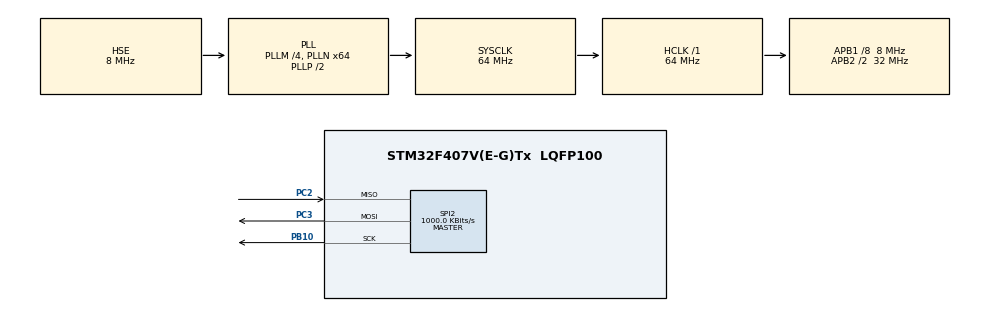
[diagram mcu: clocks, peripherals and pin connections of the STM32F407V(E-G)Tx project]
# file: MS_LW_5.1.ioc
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Mcu.Family=STM32F4
Mcu.Name=STM32F407V(E-G)Tx
Mcu.Package=LQFP100
NVIC.PriorityGroup=NVIC_PRIORITYGROUP_0
PB10.Mode=Full_Duplex_Master
PB10.Signal=SPI2_SCK
PC2.Mode=Full_Duplex_Master
PC2.Signal=SPI2_MISO
PC3.Mode=Full_Duplex_Master
PC3.Signal=SPI2_MOSI
PH0-OSC_IN.Mode=HSE-External-Oscillator
PH0-OSC_IN.Signal=RCC_OSC_IN
PH1-OSC_OUT.Mode=HSE-External-Oscillator
PH1-OSC_OUT.Signal=RCC_OSC_OUT
ProjectManager.HeapSize=0x200
ProjectManager.StackSize=0x400
ProjectManager.TargetToolchain=STM32CubeIDE
RCC.48MHZClocksFreq_Value=18285714.285714287
RCC.AHBFreq_Value=64000000
RCC.APB1CLKDivider=RCC_HCLK_DIV8
RCC.APB1Freq_Value=8000000
RCC.APB1TimFreq_Value=16000000
RCC.APB2CLKDivider=RCC_HCLK_DIV2
RCC.APB2Freq_Value=32000000
RCC.APB2TimFreq_Value=64000000
RCC.CortexFreq_Value=64000000
RCC.HCLKFreq_Value=64000000
RCC.HSE_VALUE=8000000
RCC.HSI_VALUE=16000000
RCC.PLLM=4
RCC.PLLN=64
RCC.PLLQ=7
RCC.PLLSourceVirtual=RCC_PLLSOURCE_HSE
RCC.SYSCLKFreq_VALUE=64000000
RCC.SYSCLKSource=RCC_SYSCLKSOURCE_PLLCLK
RCC.VCOOutputFreq_Value=128000000
SPI2.BaudRatePrescaler=SPI_BAUDRATEPRESCALER_8
SPI2.CalculateBaudRate=1000.0 KBits/s
SPI2.Direction=SPI_DIRECTION_2LINES
SPI2.Mode=SPI_MODE_MASTER
SPI2.VirtualType=VM_MASTER
board=STM32F407G-DISC1

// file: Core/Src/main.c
/* USER CODE BEGIN Header */
/**
  ******************************************************************************
  * @file           : main.c
  * @brief          : Main program body
  ******************************************************************************
  * @attention
  *
  * Copyright (c) 2023 STMicroelectronics.
  * All rights reserved.
  *
  * This software is licensed under terms that can be found in the LICENSE file
  * in the root directory of this software component.
  * If no LICENSE file comes with this software, it is provided AS-IS.
  *
  ******************************************************************************
  */
/* USER CODE END Header */
#include "main.h"

SPI_HandleTypeDef hspi2;

/* USER CODE BEGIN PV */
uint8_t buffer_tx[4] = {1, 3, 11, 15};
uint8_t buffer_rx[4];
/* USER CODE END PV */

void SystemClock_Config(void);
static void MX_GPIO_Init(void);
static void MX_SPI2_Init(void);

int main(void)
{

  /* MCU Configuration--------------------------------------------------------*/

  /* Reset of all peripherals, Initializes the Flash interface and the Systick. */
  HAL_Init();

  /* Configure the system clock */
  SystemClock_Config();

  /* Initialize all configured peripherals */
  MX_GPIO_Init();
  MX_SPI2_Init();
  /* USER CODE BEGIN 2 */
HAL_SPI_TransmitReceive(&hspi2, buffer_tx, buffer_rx, 4, 100);
  /* USER CODE END 2 */

  /* Infinite loop */
  while (1)
  {

  }
}

void SystemClock_Config(void)
{
  RCC_OscInitTypeDef RCC_OscInitStruct = {0};
  RCC_ClkInitTypeDef RCC_ClkInitStruct = {0};

  /** Configure the main internal regulator output voltage
  */
  __HAL_RCC_PWR_CLK_ENABLE();
  __HAL_PWR_VOLTAGESCALING_CONFIG(PWR_REGULATOR_VOLTAGE_SCALE1);

  /** Initializes the RCC Oscillators according to the specified parameters
  * in the RCC_OscInitTypeDef structure.
  */
  RCC_OscInitStruct.OscillatorType = RCC_OSCILLATORTYPE_HSE;
  RCC_OscInitStruct.HSEState = RCC_HSE_ON;
  RCC_OscInitStruct.PLL.PLLState = RCC_PLL_ON;
  RCC_OscInitStruct.PLL.PLLSource = RCC_PLLSOURCE_HSE;
  RCC_OscInitStruct.PLL.PLLM = 4;
  RCC_OscInitStruct.PLL.PLLN = 64;
  RCC_OscInitStruct.PLL.PLLP = RCC_PLLP_DIV2;
  RCC_OscInitStruct.PLL.PLLQ = 7;
  if (HAL_RCC_OscConfig(&RCC_OscInitStruct) != HAL_OK)
  {
    Error_Handler();
  }

  /** Initializes the CPU, AHB and APB buses clocks
  */
  RCC_ClkInitStruct.ClockType = RCC_CLOCKTYPE_HCLK|RCC_CLOCKTYPE_SYSCLK
                              |RCC_CLOCKTYPE_PCLK1|RCC_CLOCKTYPE_PCLK2;
  RCC_ClkInitStruct.SYSCLKSource = RCC_SYSCLKSOURCE_PLLCLK;
  RCC_ClkInitStruct.AHBCLKDivider = RCC_SYSCLK_DIV1;
  RCC_ClkInitStruct.APB1CLKDivider = RCC_HCLK_DIV8;
  RCC_ClkInitStruct.APB2CLKDivider = RCC_HCLK_DIV2;

  if (HAL_RCC_ClockConfig(&RCC_ClkInitStruct, FLASH_LATENCY_2) != HAL_OK)
  {
    Error_Handler();
  }
}

static void MX_SPI2_Init(void)
{

  /* SPI2 parameter configuration*/
  hspi2.Instance = SPI2;
  hspi2.Init.Mode = SPI_MODE_MASTER;
  hspi2.Init.Direction = SPI_DIRECTION_2LINES;
  hspi2.Init.DataSize = SPI_DATASIZE_8BIT;
  hspi2.Init.CLKPolarity = SPI_POLARITY_LOW;
  hspi2.Init.CLKPhase = SPI_PHASE_1EDGE;
  hspi2.Init.NSS = SPI_NSS_SOFT;
  hspi2.Init.BaudRatePrescaler = SPI_BAUDRATEPRESCALER_8;
  hspi2.Init.FirstBit = SPI_FIRSTBIT_MSB;
  hspi2.Init.TIMode = SPI_TIMODE_DISABLE;
  hspi2.Init.CRCCalculation = SPI_CRCCALCULATION_DISABLE;
  hspi2.Init.CRCPolynomial = 10;
  if (HAL_SPI_Init(&hspi2) != HAL_OK)
  {
    Error_Handler();
  }

}

static void MX_GPIO_Init(void)
{

  /* GPIO Ports Clock Enable */
  __HAL_RCC_GPIOH_CLK_ENABLE();
  __HAL_RCC_GPIOC_CLK_ENABLE();
  __HAL_RCC_GPIOB_CLK_ENABLE();

}

void Error_Handler(void)
{
  __disable_irq();
  while (1)
  {
  }
}
